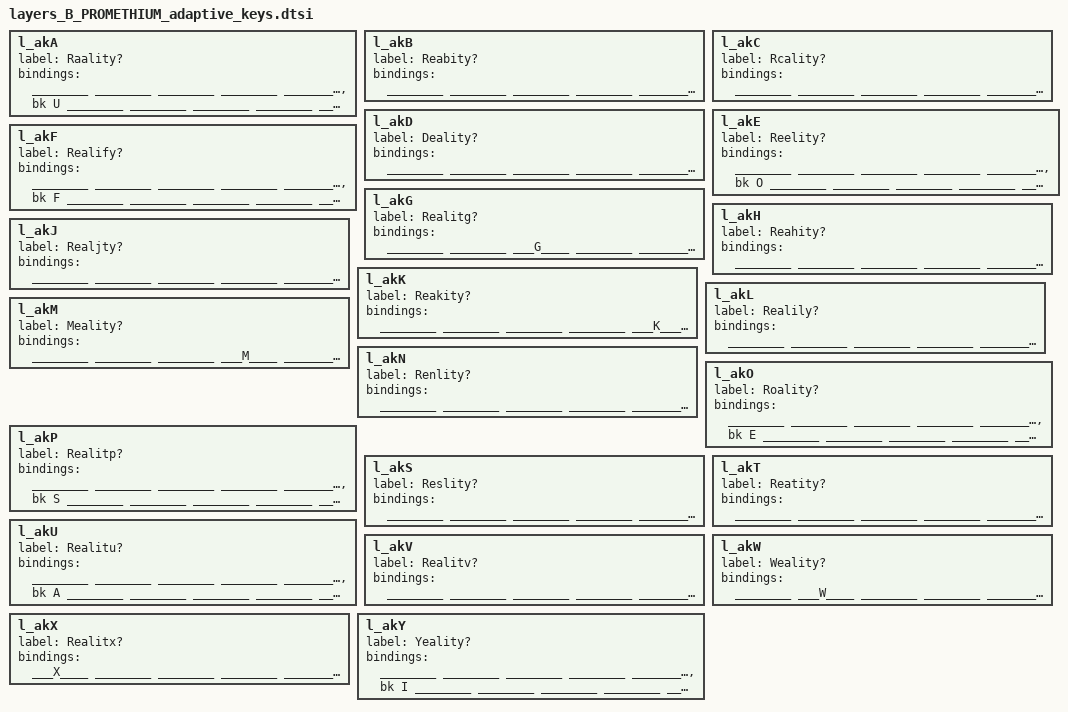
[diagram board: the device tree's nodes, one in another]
                l_akA {
                        label = "Raality?";
                        bindings = <
________   ________   ________   ________   ________          ________   ________   &bk U      ________   ________
________   ________   ________   ________   ________          ________   ___A____   ________   ________   ________
________   ________   ________   ________   ________          ________   ________   ________   ________   ________
                        ________   ________   ________      ________   ________   ________
                        >;
                };

                l_akB {
                        label = "Reabity?";
                        bindings = <
________   ________   ________   ________   ________          ________   ________   ________   ________   ________
________   ________   ________   ________   ________          ________   ________   ________   ________   ________
________   ________   ________   ________   ________          ________   ________   ________   ________   ___B____
                        ________   ________   ________      ________   ________   ________
                        >;
                };

                l_akC {
                        label = "Rcality?";
                        bindings = <
________   ________   ________   ________   ________          ________   ________   ________   ________   ________
________   ________   ________   ________   ________          ________   ________   ________   ________   ___C____
________   ________   ________   ________   ________          ________   ________   ________   ________   ________
                        ________   ________   ________      ________   ________   ________
                        >;
                };

                l_akD {
                        label = "Deality?";
                        bindings = <
________   ________   ________   ________   ________          ________   ________   ________   ________   ________
________   ________   ________   ________   ________          ________   ________   ________   ________   ________
________   ________   ___D____   ________   ________          ________   ________   ________   ________   ________
                        ________   ________   ________      ________   ________   ________
                        >;
                };

                l_akE {
                        label = "Reelity?";
                        bindings = <
________   ________   ________   ________   ________          ________   ________   ________   &bk O      ________
________   ________   ________   ________   ________          ________   ________   ___E____   ________   ________
________   ________   ________   ________   ________          ________   ________   ________   ________   ________
                        ________   ________   ________      ________   ________   ________
                        >;
                };

                l_akF {
                        label = "Realify?";
                        bindings = <
________   ________   ________   ________   ________          ________   ________   ________   ________   ________
________   ________   ________   ________   ________          ________   ________   ________   ________   ________
___F____   &bk F      ________   ________   ________          ________   ________   ________   ________   ________
                        ________   ________   ________      ________   ________   ________
                        >;
                };

                l_akG {
                        label = "Realitg?";
                        bindings = <
________   ________   ___G____   ________   ________          ________   ________   ________   ________   ________
________   ________   ________   ________   ________          ________   ________   ________   ________   ________
________   ________   ________   ________   ________          ________   ________   ________   ________   ________
                        ________   ________   ________      ________   ________   ________
                        >;
                };

                l_akH {
                        label = "Reahity?";
                        bindings = <
________   ________   ________   ________   ________          ________   ________   ________   ________   ________
________   ________   ________   ___H____   ________          ________   ________   ________   ________   ________
________   ________   ________   ________   ________          ________   ________   ________   ________   ________
                        ________   ________   ________      ________   ________   ________
                        >;
                };

                l_akJ {
                        label = "Realjty?";
                        bindings = <
________   ________   ________   ________   ________          ________   ________   ________   ________   ________
________   ________   ________   ________   ___J____          ________   ________   ________   ________   ________
________   ________   ________   ________   ________          ________   ________   ________   ________   ________
                        ________   ________   ________      ________   ________   ________
                        >;
                };

                l_akK {
                        label = "Reakity?";
                        bindings = <
________   ________   ________   ________   ___K____          ________   ________   ________   ________   ________
________   ________   ________   ________   ________          ________   ________   ________   ________   ________
________   ________   ________   ________   ________          ________   ________   ________   ________   ________
                        ________   ________   ________      ________   ________   ________
                        >;
                };


                l_akL {
                        label = "Realily?";
                        bindings = <
________   ________   ________   ________   ________          ________   ________   ________   ________   ________
________   ________   ________   ________   ________          ________   ________   ________   ________   ________
________   ________   ________   ___L____   ________          ________   ________   ________   ________   ________
                        ________   ________   ________      ________   ________   ________
                        >;
                };


                l_akM {
                        label = "Meality?";
                        bindings = <
________   ________   ________   ___M____   ________          ________   ________   ________   ________   ________
________   ________   ________   ________   ________          ________   ________   ________   ________   ________
________   ________   ________   ________   ________          ________   ________   ________   ________   ________
                        ________   ________   ________      ________   ________   ________
                        >;
                };

                l_akN {
                        label = "Renlity?";
                        bindings = <
________   ________   ________   ________   ________           ________   ________   ________   ________   ________
________   ___N____   ________   ________   ________           ________   ________   ________   ________   ________
________   ________   ________   ________   ________           ________   ________   ________   ________   ________
                        ________   ________   ________      ________   ________   ________
                        >;
                };

                l_akO {
                        label = "Roality?";
                        bindings = <
________   ________   ________   ________   ________          ________   ________   ________   &bk E      ________
________   ________   ________   ________   ________          ________   ________   ________   ________   ________
________   ________   ________   ________   ________          ________   ________   ___O____   ________   ________
                        ________   ________   ________      ________   ________   ________
                        >;
                };

                l_akP {
                        label = "Realitp?";
                        bindings = <
________   ________   ________   ________   ________          ________   ________   ________   ________   ________
________   ________   ________   ________   ________          ________   ________   ________   ________   ________
___P____   &bk S      ________   ________   ________          ________   ________   ________   ________   ________
                        ________   ________   ________      ________   ________   ________
                        >;
                };

                l_akS {
                        label = "Reslity?";
                        bindings = <
________   ________   ________   ________   ________          ________   ________   ________   ________   ________
___S____   ________   ________   ________   ________          ________   ________   ________   ________   ________
________   ________   ________   ________   ________          ________   ________   ________   ________   ________
                        ________   ________   ________      ________   ________   ________
                        >;
                };

                l_akT {
                        label = "Reatity?";
                        bindings = <
________   ________   ________   ________   ________          ________   ________   ________   ________   ________
________   ________   ___T____   ________   ________          ________   ________   ________   ________   ________
________   ________   ________   ________   ________          ________   ________   ________   ________   ________
                        ________   ________   ________      ________   ________   ________
                        >;
                };

                l_akU {
                        label = "Realitu?";
                        bindings = <
________   ________   ________   ________   ________          ________   ________   &bk A      ________   ________
________   ________   ________   ________   ________          ________   ________   ________   ________   ________
________   ________   ________   ________   ________          ________   ___U____   ________   ________   ________
                        ________   ________   ________      ________   ________   ________
                        >;
                };

                l_akV {
                        label = "Realitv?";
                        bindings = <
________   ________   ________   ________   ________          ________   ________   ________   ________   ________
________   ________   ________   ________   ________          ________   ________   ________   ________   ________
________   ________   ________   ________   ___V____          ________   ________   ________   ________   ________
                        ________   ________   ________      ________   ________   ________
                        >;
                };


                l_akW {
                        label = "Weality?";
                        bindings = <
________   ___W____   ________   ________   ________          ________   ________   ________   ________   ________
________   ________   ________   ________   ________          ________   ________   ________   ________   ________
________   ________   ________   ________   ________          ________   ________   ________   ________   ________
                        ________   ________   ________      ________   ________   ________
                        >;
                };

                l_akX {
                        label = "Realitx?";
                        bindings = <
___X____   ________   ________   ________   ________          ________   ________   ________   ________   ________
________   ________   ________   ________   ________          ________   ________   ________   ________   ________
________   ________   ________   ________   ________          ________   ________   ________   ________   ________
                        ________   ________   ________      ________   ________   ________
                        >;
                };

                l_akY {
                        label = "Yeality?";
                        bindings = <
________   ________   ________   ________   ________          ________   ________   ________   ________   ________
________   ________   ________   ________   ________          ________   ________   ________   ________   ________
________   ________   ________   ________   ________          ________   ________   ________   ___Y____   &bk I
                        ________   ________   ________      ________   ________   ________
                        >;
                };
